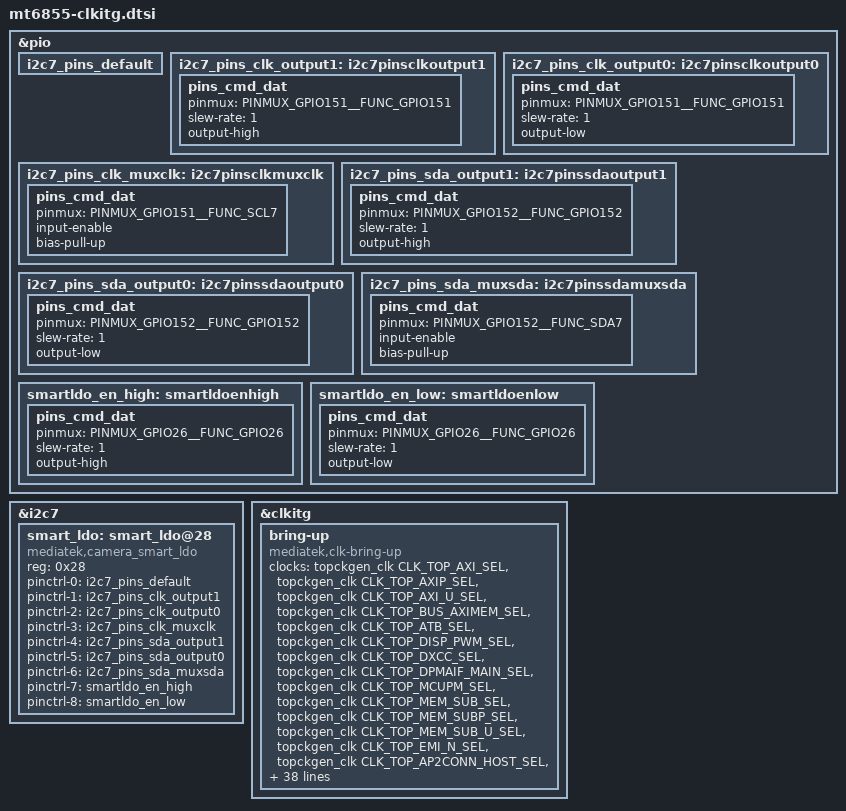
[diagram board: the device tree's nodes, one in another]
// SPDX-License-Identifier: (GPL-2.0 OR MIT)
/*
 * Copyright (C) 2021 MediaTek Inc.
 * Author: Owen Chen <owen.chen@mediatek.com>
 */

/* CAMERA SMART LDO  start */

&pio {
	i2c7_pins_default: i2c7_pins_default {
	};
	i2c7_pins_clk_output1: i2c7pinsclkoutput1 {
		pins_cmd_dat {
			pinmux = <PINMUX_GPIO151__FUNC_GPIO151>;
			slew-rate = <1>;
			output-high;
		};
	};
	i2c7_pins_clk_output0: i2c7pinsclkoutput0 {
		pins_cmd_dat {
			pinmux = <PINMUX_GPIO151__FUNC_GPIO151>;
			slew-rate = <1>;
			output-low;
		};
	};
	i2c7_pins_clk_muxclk: i2c7pinsclkmuxclk {
		pins_cmd_dat {
			pinmux = <PINMUX_GPIO151__FUNC_SCL7>;
            		input-enable;
            		bias-pull-up;
		};
	};
	i2c7_pins_sda_output1: i2c7pinssdaoutput1 {
		pins_cmd_dat {
			pinmux = <PINMUX_GPIO152__FUNC_GPIO152>;
			slew-rate = <1>;
			output-high;
		};
	};
	i2c7_pins_sda_output0: i2c7pinssdaoutput0 {
		pins_cmd_dat {
			pinmux = <PINMUX_GPIO152__FUNC_GPIO152>;
			slew-rate = <1>;
			output-low;
		};
	};
	i2c7_pins_sda_muxsda: i2c7pinssdamuxsda {
		pins_cmd_dat {
			pinmux = <PINMUX_GPIO152__FUNC_SDA7>;
            		input-enable;
            		bias-pull-up;
		};
	};
	smartldo_en_high: smartldoenhigh {
		pins_cmd_dat {
			pinmux = <PINMUX_GPIO26__FUNC_GPIO26>;
			slew-rate = <1>;
			output-high;
		};
	};
	smartldo_en_low: smartldoenlow {
		pins_cmd_dat {
			pinmux = <PINMUX_GPIO26__FUNC_GPIO26>;
			slew-rate = <1>;
			output-low;
		};
	};

};

&i2c7 {
    smart_ldo:smart_ldo@28 {
        compatible = "mediatek,camera_smart_ldo";
		reg = <0x28>;
		status = "okay";
	};
};

&smart_ldo {
    pinctrl-names = "default",  "i2c7_clk_high",
		"i2c7_clk_low", "i2c7_clk_func",
		"i2c7_sda_high","i2c7_sda_low",
		"i2c7_sda_func","smartldo_en_high",
		"smartldo_en_low";
	pinctrl-0 = <&i2c7_pins_default>;
	pinctrl-1 = <&i2c7_pins_clk_output1>;
	pinctrl-2 = <&i2c7_pins_clk_output0>;
	pinctrl-3 = <&i2c7_pins_clk_muxclk>;
	pinctrl-4 = <&i2c7_pins_sda_output1>;
	pinctrl-5 = <&i2c7_pins_sda_output0>;
	pinctrl-6 = <&i2c7_pins_sda_muxsda>;
	pinctrl-7 = <&smartldo_en_high>;
	pinctrl-8 = <&smartldo_en_low>;

	status = "okay";
};

/* CAMERA SMART LDO  end */

&clkitg {
	status = "okay";
	bring-up {
		compatible = "mediatek,clk-bring-up";
		clocks =
			<&topckgen_clk CLK_TOP_AXI_SEL>,
			<&topckgen_clk CLK_TOP_AXIP_SEL>,
			<&topckgen_clk CLK_TOP_AXI_U_SEL>,
			<&topckgen_clk CLK_TOP_BUS_AXIMEM_SEL>,
			<&topckgen_clk CLK_TOP_ATB_SEL>,
			<&topckgen_clk CLK_TOP_DISP_PWM_SEL>,
			<&topckgen_clk CLK_TOP_DXCC_SEL>,
			<&topckgen_clk CLK_TOP_DPMAIF_MAIN_SEL>,
			<&topckgen_clk CLK_TOP_MCUPM_SEL>,
			<&topckgen_clk CLK_TOP_MEM_SUB_SEL>,
			<&topckgen_clk CLK_TOP_MEM_SUBP_SEL>,
			<&topckgen_clk CLK_TOP_MEM_SUB_U_SEL>,
			<&topckgen_clk CLK_TOP_EMI_N_SEL>,
			<&topckgen_clk CLK_TOP_AP2CONN_HOST_SEL>,
			<&infracfg_ao_clk CLK_IFRAO_THERM>,
			<&infracfg_ao_clk CLK_IFRAO_CQ_DMA_FPC>,
			<&infracfg_ao_clk CLK_IFRAO_TRNG>,
			<&infracfg_ao_clk CLK_IFRAO_CCIF1_AP>,
			<&infracfg_ao_clk CLK_IFRAO_CCIF1_MD>,
			<&infracfg_ao_clk CLK_IFRAO_CCIF_AP>,
			<&infracfg_ao_clk CLK_IFRAO_DEBUGSYS>,
			<&infracfg_ao_clk CLK_IFRAO_CCIF_MD>,
			<&infracfg_ao_clk CLK_IFRAO_DXCC_AO>,
			<&infracfg_ao_clk CLK_IFRAO_DBG_TRACE>,
			<&infracfg_ao_clk CLK_IFRAO_CLDMA_BCLK>,
			<&infracfg_ao_clk CLK_IFRAO_CQ_DMA>,
			<&infracfg_ao_clk CLK_IFRAO_CCIF5_AP>,
			<&infracfg_ao_clk CLK_IFRAO_CCIF5_MD>,
			<&infracfg_ao_clk CLK_IFRAO_CCIF2_AP>,
			<&infracfg_ao_clk CLK_IFRAO_CCIF2_MD>,
			<&infracfg_ao_clk CLK_IFRAO_CCIF3_AP>,
			<&infracfg_ao_clk CLK_IFRAO_CCIF3_MD>,
			<&infracfg_ao_clk CLK_IFRAO_DEVICE_APC_SYNC>,
			<&infracfg_ao_clk CLK_IFRAO_DPMAIF_MAIN>,
			<&infracfg_ao_clk CLK_IFRAO_CCIF4_AP>,
			<&infracfg_ao_clk CLK_IFRAO_CCIF4_MD>,
			<&infracfg_ao_clk CLK_IFRAO_RG_MMW_DPMAIF26M_CK>,
			<&infracfg_ao_clk CLK_IFRAO_RG_MEM_SUB_CK>,
			<&vlp_cksys_clk CLK_VLP_CK_SCP_SEL>,
			<&vlp_cksys_clk CLK_VLP_CK_PWRAP_ULPOSC_SEL>,
			<&vlp_cksys_clk CLK_VLP_CK_DXCC_VLP_SEL>,
			<&vlp_cksys_clk CLK_VLP_CK_SPMI_P_MST_SEL>,
			<&vlp_cksys_clk CLK_VLP_CK_SPMI_M_MST_SEL>,
			<&vlp_cksys_clk CLK_VLP_CK_DVFSRC_SEL>,
			<&vlp_cksys_clk CLK_VLP_CK_PWM_VLP_SEL>,
			<&vlp_cksys_clk CLK_VLP_CK_AXI_VLP_SEL>,
			<&vlp_cksys_clk CLK_VLP_CK_DBGAO_26M_SEL>,
			<&vlp_cksys_clk CLK_VLP_CK_SYSTIMER_26M_SEL>,
			<&vlp_cksys_clk CLK_VLP_CK_SSPM_SEL>,
			<&vlp_cksys_clk CLK_VLP_CK_SSPM_F26M_SEL>,
			<&vlp_cksys_clk CLK_VLP_CK_SRCK_SEL>,
			<&vlp_cksys_clk CLK_VLP_CK_SRAMRC_SEL>;
	};
};
